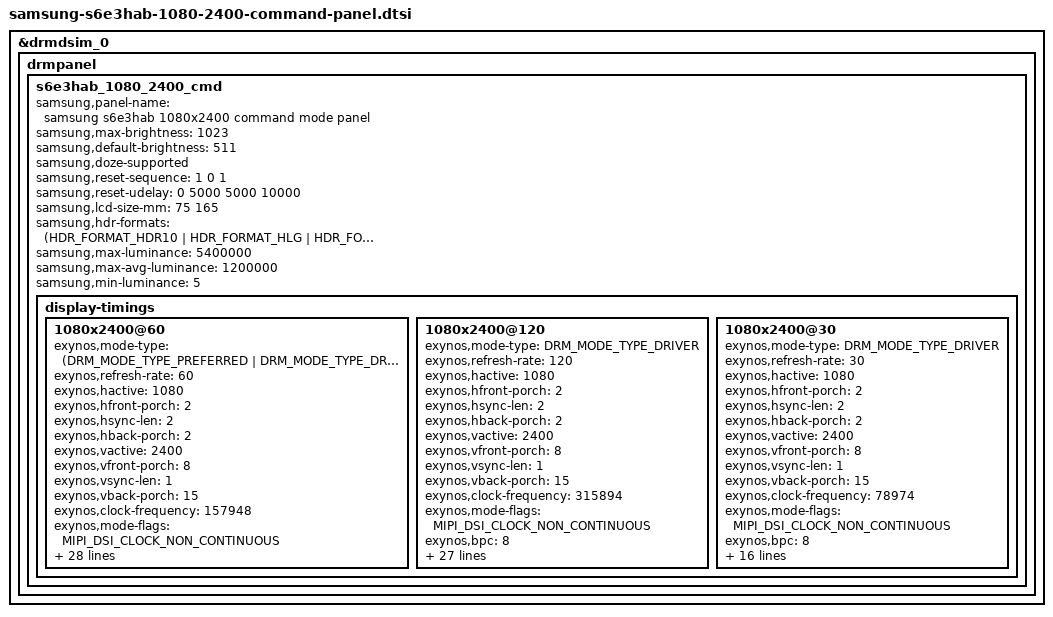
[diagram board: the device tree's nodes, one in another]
#include <dt-bindings/display/exynos-display.h>
#include <dt-bindings/display/exynos-mipi-display.h>

&drmdsim_0 {
	drmpanel {
		s6e3hab_1080_2400_cmd: s6e3hab_1080_2400_cmd {
			samsung,panel-name = "samsung s6e3hab 1080x2400 command mode panel";
			samsung,max-brightness = <1023>;
			samsung,default-brightness = <511>;
			samsung,doze-supported;

			samsung,reset-sequence = <1 0 1>;
			samsung,reset-udelay = <0 5000 5000 10000>;

			samsung,lcd-size-mm = <75 165>; /* width x height */

			samsung,hdr-formats = <(HDR_FORMAT_HDR10 | HDR_FORMAT_HLG | HDR_FORMAT_HDR10P)>;
			samsung,max-luminance = <5400000>;
			samsung,max-avg-luminance = <1200000>;
			samsung,min-luminance = <5>;

			display-timings {
				1080x2400@60 {
					exynos,mode-type = <(DRM_MODE_TYPE_PREFERRED |
							DRM_MODE_TYPE_DRIVER)>;
					exynos,refresh-rate = <60>;
					exynos,hactive = <1080>;
					exynos,hfront-porch = <2>;
					exynos,hsync-len = <2>;
					exynos,hback-porch = <2>;
					exynos,vactive = <2400>;
					exynos,vfront-porch = <8>;
					exynos,vsync-len = <1>;
					exynos,vback-porch = <15>;
					exynos,clock-frequency = <157948>;

					exynos,mode-flags = <MIPI_DSI_CLOCK_NON_CONTINUOUS>;
					exynos,bpc = <8>;
					exynos,lp-mode = <0>;
					exynos,dsc-en = <1>;
					exynos,dsc-count = <1>;
					exynos,dsc-slice-count = <2>;
					exynos,dsc-slice-height = <40>;

					exynos,pre-pps-cmds = <
						0x03 0x9F 0xA5 0xA5 0x00
						>;
					exynos,pps-cmds = <
						0x58
						0x11 0x00 0x00 0x89 0x30 0x80 0x09 0x60
						0x04 0x38 0x00 0x28 0x02 0x1C 0x02 0x1C
						0x02 0x00 0x02 0x0E 0x00 0x20 0x03 0xDD
						0x00 0x07 0x00 0x0C 0x02 0x77 0x02 0x8B
						0x18 0x00 0x10 0xF0 0x03 0x0C 0x20 0x00
						0x06 0x0B 0x0B 0x33 0x0E 0x1C 0x2A 0x38
						0x46 0x54 0x62 0x69 0x70 0x77 0x79 0x7B
						0x7D 0x7E 0x01 0x02 0x01 0x00 0x09 0x40
						0x09 0xBE 0x19 0xFC 0x19 0xFA 0x19 0xF8
						0x1A 0x38 0x1A 0x78 0x1A 0xB6 0x2A 0xF6
						0x2B 0x34 0x2B 0x74 0x3B 0x74 0x6B 0xF4
						0x00
						>;
					exynos,post-pps-cmds = <
						0x03 0x9F 0x5A 0x5A 0x00
						>;
					exynos,on-cmds = <
						0x03 0xF0 0x5A 0x5A 0x00
						0x03 0xFC 0x5A 0x5A 0x00
						/* sleep out: 200ms delay */
						0x01 0x11 0xC8
						0x0A 0xB9 0x00 0xC0 0x8C 0x09 0x00 0x00 0x00 0x11 0x03 0x00
						/*  enable brightness control */
						0x02 0x53 0x20 0x00

						/* WRDISBV(51h) = 1st[7:0], 2nd[15:8] */
						0x03 0x51 0xFF 0x7F 0x00

						/* TE on */
						0x01 0x35 0x00

						/* ESD flag: [2]=VLIN3, [6]=VLIN1 error check */
						0x03 0xED 0x04 0x44 0x00
						/* Typical high duration */
						0x05 0xB9 0x00 0xC0 0x8C 0x09 0x00
						>;
					exynos,tectrl-cmds = <
						0x03 0xF0 0x5A 0x5A 0x00
						0x05 0xB9 0x01 0xB0 0xC4 0x09 0x00
						0x03 0xF0 0xA5 0xA5 0x00
						>;
					exynos,vref-cmds = <
						0x03 0xF0 0x5A 0x5A 0x00
						0x03 0x9F 0xA5 0xA5 0x00
						0x02 0x60 0x00 0x00
						0x03 0x9F 0x5A 0x5A 0x00
						0x02 0xF7 0x0F 0x00
						0x03 0xF0 0xA5 0xA5 0x00
						>;
					exynos,mres-cmds = <
						0x05 0x2A 0x00 0x00 0x04 0x37 0x00
						0x05 0x2B 0x00 0x00 0x09 0x5F 0x00
						0x03 0xF0 0x5A 0x5A 0x00
						0x02 0xBA 0x02 0x00
						0x03 0xF0 0xA5 0xA5 0x00
						>;
					exynos,disp-on-cmds = <
						0x03 0x9F 0xA5 0xA5 0x00
						0x01 0x29 0x00
						0x03 0x9F 0x5A 0x5A 0x00
						>;
					exynos,off-cmds = <
						0x01 0x10 0x00
						0x01 0x28 0x00
						>;

					exynos,rcd-block-rect = <0 100 1080 2200>;
					exynos,rcd-top-pos = <0 0>;
					exynos,rcd-top-img = /bits/ 8 <
						0xFF 0xFF 0xFF 0xFF 0xFF 0xFF 0xFF 0xFF 0xFF 0xFF 0xFF 0xFF 0xFF 0xFF 0xFF 0xFF
						0xFF 0xFF 0xFF 0xFF 0xFF 0x95 0x00 0x03 0xFF 0xFF 0xFF 0xFF 0xFF 0xFF 0xFF 0xFF
						0xFF 0x38 0x00 0x05 0xFF 0xFF 0xFF 0xFF 0xFF 0xFF 0xFF 0xFF 0xFF 0x36 0x00 0x07
						0xFF 0xFF 0xFF 0xFF 0xFF 0xFF 0xFF 0xFF 0xFF 0x34 0x00 0x09 0xFF 0xFF 0xFF 0xFF
						0xFF 0xFF 0xFF 0xFF 0xFF 0x32 0x00 0x0B 0xFF 0xFF 0xFF 0xFF 0xFF 0xFF 0xFF 0xFF
						0xFF 0x30 0x00 0x0D 0xFF 0xFF 0xFF 0xFF 0xFF 0xFF 0xFF 0xFF 0xFF 0x2E 0x00 0x0F
						0xFF 0xFF 0xFF 0xFF 0xFF 0xFF 0xFF 0xFF 0xFF 0x2C 0x00 0x11 0xFF 0xFF 0xFF 0xFF
						0xFF 0xFF 0xFF 0xFF 0xFF 0x2A 0x00 0x13 0xFF 0xFF 0xFF 0xFF 0xFF 0xFF 0xFF 0xFF
						0xFF 0x28 0x00 0x15 0xFF 0xFF 0xFF 0xFF 0xFF 0xFF 0xFF 0xFF 0xFF 0x26 0x00 0x17
						0xFF 0xFF 0xFF 0xFF 0xFF 0xFF 0xFF 0xFF 0xFF 0x24 0x00 0x19 0xFF 0xFF 0xFF 0xFF
						0xFF 0xFF 0xFF 0xFF 0xFF 0x22 0x00 0x1B 0xFF 0xFF 0xFF 0xFF 0xFF 0xFF 0xFF 0xFF
						0xFF 0x20 0x00 0x1D 0xFF 0xFF 0xFF 0xFF 0xFF 0xFF 0xFF 0xFF 0xFF 0x1E 0x00 0x1F
						0xFF 0xFF 0xFF 0xFF 0xFF 0xFF 0xFF 0xFF 0xFF 0x1C 0x00 0x21 0xFF 0xFF 0xFF 0xFF
						0xFF 0xFF 0xFF 0xFF 0xFF 0x1A 0x00 0x23 0xFF 0xFF 0xFF 0xFF 0xFF 0xFF 0xFF 0xFF
						0xFF 0x18 0x00 0x25 0xFF 0xFF 0xFF 0xFF 0xFF 0xFF 0xFF 0xFF 0xFF 0x16 0x00 0x27
						0xFF 0xFF 0xFF 0xFF 0xFF 0xFF 0xFF 0xFF 0xFF 0x14 0x00 0x29 0xFF 0xFF 0xFF 0xFF
						0xFF 0xFF 0xFF 0xFF 0xFF 0x12 0x00 0x2B 0xFF 0xFF 0xFF 0xFF 0xFF 0xFF 0xFF 0xFF
						0xFF 0x10 0x00 0x2D 0xFF 0xFF 0xFF 0xFF 0xFF 0xFF 0xFF 0xFF 0xFF 0x0E 0x00 0x2F
						0xFF 0xFF 0xFF 0xFF 0xFF 0xFF 0xFF 0xFF 0xFF 0x0C 0x00 0x31 0xFF 0xFF 0xFF 0xFF
						0xFF 0xFF 0xFF 0xFF 0xFF 0x0A 0x00 0x33 0xFF 0xFF 0xFF 0xFF 0xFF 0xFF 0xFF 0xFF
						0xFF 0x08 0x00 0x35 0xFF 0xFF 0xFF 0xFF 0xFF 0xFF 0xFF 0xFF 0xFF 0x06 0x00 0x37
						0xFF 0xFF 0xFF 0xFF 0xFF 0xFF 0xFF 0xFF 0xFF 0x04 0x00 0x39 0xFF 0xFF 0xFF 0xFF
						0xFF 0xFF 0xFF 0xFF 0xFF 0x02 0x00 0x3B 0xFF 0xFF 0xFF 0xFF 0xFF 0xFF 0xFF 0xFF
						0x00 0x3D 0xFF 0xFF 0xFF 0xFF 0xFF 0xFF 0xFF 0xFD 0x00 0x3F 0xFF 0xFF 0xFF 0xFF
						0xFF 0xFF 0xFF 0xFB 0x00 0x41 0xFF 0xFF 0xFF 0xFF 0xFF 0xFF 0xFF 0xF9 0x00 0x43
						0xFF 0xFF 0xFF 0xFF 0xFF 0xFF 0xFF 0xF7 0x00 0x45 0xFF 0xFF 0xFF 0xFF 0xFF 0xFF
						0xFF 0xF5 0x00 0x47 0xFF 0xFF 0xFF 0xFF 0xFF 0xFF 0xFF 0xF3 0x00 0x49 0xFF 0xFF
						0xFF 0xFF 0xFF 0xFF 0xFF 0xF1 0x00 0x4B 0xFF 0xFF 0xFF 0xFF 0xFF 0xFF 0xFF 0xEF
						0x00 0x4D 0xFF 0xFF 0xFF 0xFF 0xFF 0xFF 0xFF 0xED 0x00 0x4F 0xFF 0xFF 0xFF 0xFF
						0xFF 0xFF 0xFF 0xEB 0x00 0x51 0xFF 0xFF 0xFF 0xFF 0xFF 0xFF 0xFF 0xE9 0x00 0x53
						0xFF 0xFF 0xFF 0xFF 0xFF 0xFF 0xFF 0xE7 0x00 0x55 0xFF 0xFF 0xFF 0xFF 0xFF 0xFF
						0xFF 0xE6 0x00 0x55 0xFF 0xFF 0xFF 0xFF 0xFF 0xFF 0xFF 0xE6 0x00 0x55 0xFF 0xFF
						0xFF 0xFF 0xFF 0xFF 0xFF 0xE7 0x00 0x53 0xFF 0xFF 0xFF 0xFF 0xFF 0xFF 0xFF 0xE9
						0x00 0x51 0xFF 0xFF 0xFF 0xFF 0xFF 0xFF 0xFF 0xEB 0x00 0x4F 0xFF 0xFF 0xFF 0xFF
						0xFF 0xFF 0xFF 0xED 0x00 0x4D 0xFF 0xFF 0xFF 0xFF 0xFF 0xFF 0xFF 0xEF 0x00 0x4B
						0xFF 0xFF 0xFF 0xFF 0xFF 0xFF 0xFF 0xF1 0x00 0x49 0xFF 0xFF 0xFF 0xFF 0xFF 0xFF
						0xFF 0xF3 0x00 0x47 0xFF 0xFF 0xFF 0xFF 0xFF 0xFF 0xFF 0xF5 0x00 0x45 0xFF 0xFF
						0xFF 0xFF 0xFF 0xFF 0xFF 0xF7 0x00 0x43 0xFF 0xFF 0xFF 0xFF 0xFF 0xFF 0xFF 0xF9
						0x00 0x41 0xFF 0xFF 0xFF 0xFF 0xFF 0xFF 0xFF 0xFB 0x00 0x3F 0xFF 0xFF 0xFF 0xFF
						0xFF 0xFF 0xFF 0xFD 0x00 0x3D 0xFF 0xFF 0xFF 0xFF 0xFF 0xFF 0xFF 0xFF 0x00 0x3B
						0xFF 0xFF 0xFF 0xFF 0xFF 0xFF 0xFF 0xFF 0xFF 0x02 0x00 0x39 0xFF 0xFF 0xFF 0xFF
						0xFF 0xFF 0xFF 0xFF 0xFF 0x04 0x00 0x37 0xFF 0xFF 0xFF 0xFF 0xFF 0xFF 0xFF 0xFF
						0xFF 0x06 0x00 0x35 0xFF 0xFF 0xFF 0xFF 0xFF 0xFF 0xFF 0xFF 0xFF 0x08 0x00 0x33
						0xFF 0xFF 0xFF 0xFF 0xFF 0xFF 0xFF 0xFF 0xFF 0x0A 0x00 0x31 0xFF 0xFF 0xFF 0xFF
						0xFF 0xFF 0xFF 0xFF 0xFF 0x0C 0x00 0x2F 0xFF 0xFF 0xFF 0xFF 0xFF 0xFF 0xFF 0xFF
						0xFF 0x0E 0x00 0x2D 0xFF 0xFF 0xFF 0xFF 0xFF 0xFF 0xFF 0xFF 0xFF 0x10 0x00 0x2B
						0xFF 0xFF 0xFF 0xFF 0xFF 0xFF 0xFF 0xFF 0xFF 0x12 0x00 0x29 0xFF 0xFF 0xFF 0xFF
						0xFF 0xFF 0xFF 0xFF 0xFF 0x14 0x00 0x27 0xFF 0xFF 0xFF 0xFF 0xFF 0xFF 0xFF 0xFF
						0xFF 0x16 0x00 0x25 0xFF 0xFF 0xFF 0xFF 0xFF 0xFF 0xFF 0xFF 0xFF 0x18 0x00 0x23
						0xFF 0xFF 0xFF 0xFF 0xFF 0xFF 0xFF 0xFF 0xFF 0x1A 0x00 0x21 0xFF 0xFF 0xFF 0xFF
						0xFF 0xFF 0xFF 0xFF 0xFF 0x1C 0x00 0x1F 0xFF 0xFF 0xFF 0xFF 0xFF 0xFF 0xFF 0xFF
						0xFF 0x1E 0x00 0x1D 0xFF 0xFF 0xFF 0xFF 0xFF 0xFF 0xFF 0xFF 0xFF 0x20 0x00 0x1B
						0xFF 0xFF 0xFF 0xFF 0xFF 0xFF 0xFF 0xFF 0xFF 0x22 0x00 0x19 0xFF 0xFF 0xFF 0xFF
						0xFF 0xFF 0xFF 0xFF 0xFF 0x24 0x00 0x17 0xFF 0xFF 0xFF 0xFF 0xFF 0xFF 0xFF 0xFF
						0xFF 0x26 0x00 0x15 0xFF 0xFF 0xFF 0xFF 0xFF 0xFF 0xFF 0xFF 0xFF 0x28 0x00 0x13
						0xFF 0xFF 0xFF 0xFF 0xFF 0xFF 0xFF 0xFF 0xFF 0x2A 0x00 0x11 0xFF 0xFF 0xFF 0xFF
						0xFF 0xFF 0xFF 0xFF 0xFF 0x2C 0x00 0x0F 0xFF 0xFF 0xFF 0xFF 0xFF 0xFF 0xFF 0xFF
						0xFF 0x2E 0x00 0x0D 0xFF 0xFF 0xFF 0xFF 0xFF 0xFF 0xFF 0xFF 0xFF 0x30 0x00 0x0B
						0xFF 0xFF 0xFF 0xFF 0xFF 0xFF 0xFF 0xFF 0xFF 0x32 0x00 0x09 0xFF 0xFF 0xFF 0xFF
						0xFF 0xFF 0xFF 0xFF 0xFF 0x34 0x00 0x07 0xFF 0xFF 0xFF 0xFF 0xFF 0xFF 0xFF 0xFF
						0xFF 0x36 0x00 0x05 0xFF 0xFF 0xFF 0xFF 0xFF 0xFF 0xFF 0xFF 0xFF 0x38 0x00 0x03
						0xFF 0xFF 0xFF 0xFF 0xFF 0xFF 0xFF 0xFF 0xFF 0xFF 0xFF 0xFF 0xFF 0xFF 0xFF 0xFF
						0xFF 0xFF 0xFF 0xFF 0xFF 0xFF 0xFF 0xFF 0xFF 0xFF 0xFF 0xFF 0xFF 0xFF 0xFF 0xFF
						0xFF 0xFF 0xFF 0xFF 0xFF 0xFF 0xFF 0xFF 0xFF 0xFF 0xFF 0xFF 0xFF 0xFF 0xFF 0xFF
						0xFF 0xFF 0xFF 0xFF 0xFF 0xFF 0xFF 0xFF 0xFF 0xFF 0xFF 0xFF 0xFF 0xFF 0xFF 0xFF
						0xFF 0xFF 0xFF 0xFF 0xFF 0xFF 0xFF 0xFF 0xFF 0xFF 0xFF 0xFF 0xFF 0xFF 0xFF 0xFF
						0xFF 0xFF 0xFF 0xFF 0xFF 0xFF 0xFF 0xFF 0xFF 0xFF 0xFF 0xFF 0xFF 0xFF 0xFF 0xFF
						0xFF 0xFF 0xFF 0xFF 0xFF 0xFF 0xFF 0xFF 0xFF 0xFF 0xFF 0xFF 0xFF 0xFF 0xFF 0xFF
						0xFF 0xFF 0xFF 0x2B
						>;

					exynos,rcd-bot-pos = <0 2300>;
					exynos,rcd-bot-img = /bits/ 8 <
						0xFF 0xFF 0xFF 0xFF 0xFF 0xFF 0xFF 0xFF 0xFF 0xFF 0xFF 0xFF 0xFF 0xFF 0xFF 0xFF
						0xFF 0xFF 0xFF 0xFF 0xFF 0xFF 0xFF 0xFF 0xFF 0xFF 0xFF 0xFF 0xFF 0xFF 0xFF 0xFF
						0xFF 0xFF 0xFF 0xFF 0xFF 0xFF 0xFF 0xFF 0xFF 0xFF 0xFF 0xFF 0xFF 0xFF 0xFF 0xFF
						0xFF 0xFF 0xFF 0xFF 0xFF 0xFF 0xFF 0xFF 0xFF 0xFF 0xFF 0xFF 0xFF 0xFF 0xFF 0xFF
						0xFF 0xFF 0xFF 0xFF 0xFF 0xFF 0xFF 0xFF 0xFF 0xFF 0xFF 0xFF 0xFF 0xFF 0xFF 0xFF
						0xFF 0xFF 0xFF 0xFF 0xFF 0xFF 0xFF 0xFF 0xFF 0xFF 0xFF 0xFF 0xFF 0xFF 0xFF 0xFF
						0xFF 0xFF 0xFF 0xFF 0xFF 0xFF 0xFF 0xFF 0xFF 0xFF 0xFF 0xFF 0xFF 0xFF 0xFF 0xFF
						0xFF 0xFF 0xFF 0xFF 0xFF 0xFF 0xFF 0xFF 0xFF 0xFF 0xFF 0xFF 0xFF 0xFF 0xFF 0xFF
						0xFF 0xFF 0xFF 0xFF 0xFF 0xFF 0xFF 0xFF 0xFF 0xFF 0xFF 0xFF 0xFF 0xFF 0xFF 0xFF
						0xFF 0xFF 0xFF 0xFF 0xFF 0xFF 0xFF 0xFF 0xFF 0xFF 0xFF 0xFF 0xFF 0xFF 0xFF 0xFF
						0xFF 0xFF 0xFF 0xFF 0xFF 0xFF 0xFF 0xFF 0xFF 0xFF 0xFF 0xFF 0xFF 0xFF 0xFF 0xFF
						0xFF 0xFF 0xFF 0xFF 0xFF 0xFF 0xFF 0xFF 0xFF 0xFF 0xFF 0xFF 0xFF 0xFF 0xFF 0xFF
						0xFF 0xFF 0xFF 0xFF 0xFF 0xFF 0xFF 0xFF 0xFF 0xFF 0xFF 0xFF 0xFF 0xFF 0xFF 0xFF
						0xFF 0xFF 0xFF 0xFF 0xFF 0xFF 0xFF 0xFF 0xFF 0xFF 0xFF 0xFF 0xFF 0xFF 0xFF 0xFF
						0xFF 0xFF 0xFF 0xFF 0xFF 0xFF 0xFF 0xFF 0xFF 0xFF 0xFF 0xFF 0xFF 0xFF 0xFF 0xFF
						0xFF 0xFF 0xFF 0xFF 0xFF 0xFF 0xFF 0xFF 0xFF 0xFF 0xFF 0xFF 0xFF 0xFF 0xFF 0xFF
						0xFF 0xFF 0xFF 0xFF 0xFF 0xFF 0xFF 0xFF 0xFF 0xFF 0xFF 0xFF 0xFF 0xFF 0xFF 0xFF
						0xFF 0xFF 0xFF 0xFF 0xFF 0xFF 0xFF 0xFF 0xFF 0xFF 0xFF 0xFF 0xFF 0xFF 0xFF 0xFF
						0xFF 0xFF 0xFF 0xFF 0xFF 0xFF 0xFF 0xFF 0xFF 0xFF 0xFF 0xFF 0xFF 0xFF 0xFF 0xFF
						0xFF 0xFF 0xFF 0xFF 0xFF 0xFF 0xFF 0xFF 0xFF 0xFF 0xFF 0xFF 0xFF 0xFF 0xFF 0xFF
						0xFF 0xFF 0xFF 0xFF 0xFF 0xFF 0xFF 0xFF 0xFF 0xFF 0xFF 0xFF 0xFF 0xFF 0xFF 0xFF
						0xFF 0xFF 0xFF 0xFF 0xFF 0xFF 0xFF 0xFF 0xFF 0xFF 0xFF 0xFF 0xFF 0xFF 0xFF 0xFF
						0xFF 0xFF 0xFF 0xFF 0xFF 0xFF 0xFF 0xFF 0xFF 0xFF 0xFF 0xFF 0xFF 0xFF 0xFF 0xFF
						0xFF 0xFF 0xFF 0xFF 0xFF 0xFF 0xFF 0xFF 0xFF 0xFF 0xFF 0xFF 0xFF 0xFF 0xFF 0xFF
						0xFF 0xFF 0xFF 0xFF 0xFF 0xFF 0xFF 0xFF 0xFF 0xFF 0xFF 0xFF 0xFF 0xFF 0xFF 0xFF
						0xFF 0xFF 0xFF 0xFF 0xFF 0xFF 0xFF 0xFF 0xFF 0xFF 0xFF 0xFF 0xFF 0xFF 0xFF 0xFF
						0xFF 0xFF 0xFF 0xFF 0xFF 0xFF 0xFF 0xFF 0xFF 0xFF 0xFF 0xFF 0xFF 0xFF 0xFF 0xFF
						0xFF 0xFF 0xFF 0xFF 0xFF 0xFF 0xFF 0xFF 0xFF 0xFF 0xFF 0xFF 0xFF 0xFF 0xFF 0xFF
						0xFF 0xFF 0xFF 0xFF 0xFF 0xFF 0xFF 0xFF 0xFF 0xFF 0xFF 0xFF 0xFF 0xFF 0xFF 0xFF
						0xFF 0xFF 0xFF 0xFF 0xFF 0xFF 0xFF 0xFF 0xFF 0xFF 0xFF 0xFF 0xFF 0xFF 0xFF 0xFF
						0xFF 0xFF 0xFF 0xFF 0xFF 0xFF 0xFF 0xFF 0xFF 0xFF 0xFF 0xFF 0xFF 0xFF 0xFF 0xFF
						0xFF 0xFF 0xFF 0xFF 0xFF 0xFF 0xFF 0xFF 0xFF 0xFF 0xFF 0xFF 0xFF 0xFF 0xFF 0xFF
						0xFF 0xFF 0xFF 0xFF 0xFF 0xFF 0xFF 0xFF 0xFF 0xFF 0xFF 0xFF 0xFF 0xFF 0xFF 0xFF
						0xFF 0xFF 0xFF 0xFF 0xFF 0xFF 0xFF 0xFF 0xFF 0xFF 0xFF 0xFF 0xFF 0xFF 0xFF 0xFF
						0xFF 0xFF 0xFF 0xFF 0xFF 0xFF 0xFF 0xFF 0xFF 0xFF 0xFF 0xFF 0xFF 0xFF 0xFF 0xFF
						0xFF 0xFF 0xFF 0xFF 0xFF 0xFF 0xFF 0xFF 0xFF 0xFF 0xFF 0xFF 0xFF 0xFF 0xFF 0xFF
						0xFF 0xFF 0xFF 0xFF 0xFF 0xFF 0xFF 0xFF 0xFF 0xFF 0xFF 0xFF 0xFF 0xFF 0xFF 0xFF
						0xFF 0xFF 0xFF 0xFF 0xFF 0xFF 0xFF 0xFF 0xFF 0xFF 0xFF 0xFF 0xFF 0xFF 0xFF 0xFF
						0xFF 0xFF 0xFF 0xFF 0xFF 0xFF 0xFF 0xFF 0xFF 0xFF 0xFF 0xFF 0xFF 0xFF 0xFF 0xFF
						0xFF 0xFF 0xFF 0xFF 0xFF 0xFF 0xFF 0xFF 0xFF 0xFF 0xFF 0xFF 0xFF 0xFF 0xFF 0xFF
						0xFF 0xFF 0xFF 0xFF 0xFF 0xFF 0xFF 0xFF 0xFF 0xFF 0xFF 0xFF 0xFF 0xFF 0xFF 0xFF
						0xFF 0xFF 0xFF 0xFF 0xFF 0xFF 0xFF 0xFF 0xFF 0xFF 0xFF 0xFF 0xFF 0xFF 0xFF 0xFF
						0xFF 0xFF 0xFF 0xFF 0xFF 0xFF 0xFF 0xFF 0xFF 0xFF 0xFF 0xFF 0xFF 0xFF 0xFF 0xFF
						0xFF 0xFF 0xFF 0xFF 0xFF 0xFF 0xFF 0xFF 0xFF 0xFF 0xFF 0xFF 0xFF 0xFF 0xFF 0xFF
						0xFF 0xFF 0xFF 0xFF 0xFF 0xFF 0xFF 0xFF 0xFF 0xFF 0xFF 0xFF 0xFF 0xFF 0xFF 0xFF
						0xFF 0xFF 0xFF 0xFF 0xFF 0xFF 0xFF 0xFF 0xFF 0xFF 0xFF 0xFF 0xFF 0xFF 0xFF 0xFF
						0xFF 0xFF 0xFF 0xFF 0xFF 0xFF 0xFF 0xFF 0xFF 0xFF 0xFF 0xFF 0xFF 0xFF 0xFF 0xFF
						0xFF 0xFF 0xFF 0xFF 0xFF 0xFF 0xFF 0xFF 0xFF 0xFF 0xFF 0xFF 0xFF 0xFF 0xFF 0xFF
						0xFF 0xFF 0xFF 0xFF 0xFF 0xFF 0xFF 0xFF 0xFF 0xFF 0xFF 0xFF 0xFF 0xFF 0xFF 0xFF
						0xFF 0xFF 0xFF 0xFF 0xFF 0xFF 0xFF 0xFF 0xFF 0xFF 0xFF 0xFF 0xFF 0xFF 0xFF 0xFF
						0xFF 0xFF 0xFF 0xFF 0xFF 0xFF 0xFF 0xFF 0xFF 0xFF 0xFF 0xFF 0xFF 0xFF 0xFF 0xFF
						0xFF 0xFF 0xFF 0xFF 0xFF 0xFF 0xFF 0xFF 0xFF 0xFF 0xFF 0xFF 0xFF 0xFF 0xFF 0xFF
						0xFF 0xFF 0xFF 0xFF 0xFF 0xFF 0xFF 0xFF 0xFF 0xFF 0xFF 0xFF 0xFF 0xFF 0xFF 0x87
						>;
				};
				1080x2400@120 {
					exynos,mode-type = <DRM_MODE_TYPE_DRIVER>;
					exynos,refresh-rate = <120>;
					exynos,hactive = <1080>;
					exynos,hfront-porch = <2>;
					exynos,hsync-len = <2>;
					exynos,hback-porch = <2>;
					exynos,vactive = <2400>;
					exynos,vfront-porch = <8>;
					exynos,vsync-len = <1>;
					exynos,vback-porch = <15>;
					exynos,clock-frequency = <315894>;

					exynos,mode-flags = <MIPI_DSI_CLOCK_NON_CONTINUOUS>;
					exynos,bpc = <8>;
					exynos,lp-mode = <0>;
					exynos,dsc-en = <1>;
					exynos,dsc-count = <1>;
					exynos,dsc-slice-count = <2>;
					exynos,dsc-slice-height = <40>;

					exynos,pre-pps-cmds = <
						0x03 0x9F 0xA5 0xA5 0x00
						>;
					exynos,pps-cmds = <
						0x58
						0x11 0x00 0x00 0x89 0x30 0x80 0x09 0x60
						0x04 0x38 0x00 0x28 0x02 0x1C 0x02 0x1C
						0x02 0x00 0x02 0x0E 0x00 0x20 0x03 0xDD
						0x00 0x07 0x00 0x0C 0x02 0x77 0x02 0x8B
						0x18 0x00 0x10 0xF0 0x03 0x0C 0x20 0x00
						0x06 0x0B 0x0B 0x33 0x0E 0x1C 0x2A 0x38
						0x46 0x54 0x62 0x69 0x70 0x77 0x79 0x7B
						0x7D 0x7E 0x01 0x02 0x01 0x00 0x09 0x40
						0x09 0xBE 0x19 0xFC 0x19 0xFA 0x19 0xF8
						0x1A 0x38 0x1A 0x78 0x1A 0xB6 0x2A 0xF6
						0x2B 0x34 0x2B 0x74 0x3B 0x74 0x6B 0xF4
						0x00
						>;
					exynos,post-pps-cmds = <
						0x03 0x9F 0x5A 0x5A 0x00
						>;
					exynos,on-cmds = <
						0x03 0xF0 0x5A 0x5A 0x00
						0x03 0xFC 0x5A 0x5A 0x00
						/* sleep out: 200ms delay */
						0x01 0x11 0xC8
						0x0A 0xB9 0x00 0xC0 0x8C 0x09 0x00 0x00 0x00 0x11 0x03 0x00
						/*  enable brightness control */
						0x02 0x53 0x20 0x00

						/* WRDISBV(51h) = 1st[7:0], 2nd[15:8] */
						0x03 0x51 0xFF 0x7F 0x00

						/* TE on */
						0x01 0x35 0x00

						/* ESD flag: [2]=VLIN3, [6]=VLIN1 error check */
						0x03 0xED 0x04 0x44 0x00
						/* Typical high duration */
						0x05 0xB9 0x00 0xC0 0x8C 0x09 0x00
						>;
					exynos,tectrl-cmds = <
						0x03 0xF0 0x5A 0x5A 0x00
						0x05 0xB9 0x01 0xA0 0xFC 0x09 0x00
						0x03 0xF0 0xA5 0xA5 0x00
						>;
					exynos,vref-cmds = <
						0x03 0xF0 0x5A 0x5A 0x00
						0x03 0x9F 0xA5 0xA5 0x00
						0x02 0x60 0x20 0x00
						0x03 0x9F 0x5A 0x5A 0x00
						0x02 0xF7 0x0F 0x00
						0x03 0xF0 0xA5 0xA5 0x00
						>;
					exynos,mres-cmds = <
						0x05 0x2A 0x00 0x00 0x04 0x37 0x00
						0x05 0x2B 0x00 0x00 0x09 0x5F 0x00
						0x03 0xF0 0x5A 0x5A 0x00
						0x02 0xBA 0x02 0x00
						0x03 0xF0 0xA5 0xA5 0x00
						>;
					exynos,disp-on-cmds = <
						0x03 0x9F 0xA5 0xA5 0x00
						0x01 0x29 0x00
						0x03 0x9F 0x5A 0x5A 0x00
						>;
					exynos,off-cmds = <
						0x01 0x10 0x00
						0x01 0x28 0x00
						>;

					exynos,rcd-block-rect = <0 100 1080 2200>;
					exynos,rcd-top-pos = <0 0>;
					exynos,rcd-top-img = /bits/ 8 <
						0xFF 0xFF 0xFF 0xFF 0xFF 0xFF 0xFF 0xFF 0xFF 0xFF 0xFF 0xFF 0xFF 0xFF 0xFF 0xFF
						0xFF 0xFF 0xFF 0xFF 0xFF 0x95 0x00 0x03 0xFF 0xFF 0xFF 0xFF 0xFF 0xFF 0xFF 0xFF
						0xFF 0x38 0x00 0x05 0xFF 0xFF 0xFF 0xFF 0xFF 0xFF 0xFF 0xFF 0xFF 0x36 0x00 0x07
						0xFF 0xFF 0xFF 0xFF 0xFF 0xFF 0xFF 0xFF 0xFF 0x34 0x00 0x09 0xFF 0xFF 0xFF 0xFF
						0xFF 0xFF 0xFF 0xFF 0xFF 0x32 0x00 0x0B 0xFF 0xFF 0xFF 0xFF 0xFF 0xFF 0xFF 0xFF
						0xFF 0x30 0x00 0x0D 0xFF 0xFF 0xFF 0xFF 0xFF 0xFF 0xFF 0xFF 0xFF 0x2E 0x00 0x0F
						0xFF 0xFF 0xFF 0xFF 0xFF 0xFF 0xFF 0xFF 0xFF 0x2C 0x00 0x11 0xFF 0xFF 0xFF 0xFF
						0xFF 0xFF 0xFF 0xFF 0xFF 0x2A 0x00 0x13 0xFF 0xFF 0xFF 0xFF 0xFF 0xFF 0xFF 0xFF
						0xFF 0x28 0x00 0x15 0xFF 0xFF 0xFF 0xFF 0xFF 0xFF 0xFF 0xFF 0xFF 0x26 0x00 0x17
						0xFF 0xFF 0xFF 0xFF 0xFF 0xFF 0xFF 0xFF 0xFF 0x24 0x00 0x19 0xFF 0xFF 0xFF 0xFF
						0xFF 0xFF 0xFF 0xFF 0xFF 0x22 0x00 0x1B 0xFF 0xFF 0xFF 0xFF 0xFF 0xFF 0xFF 0xFF
						0xFF 0x20 0x00 0x1D 0xFF 0xFF 0xFF 0xFF 0xFF 0xFF 0xFF 0xFF 0xFF 0x1E 0x00 0x1F
						0xFF 0xFF 0xFF 0xFF 0xFF 0xFF 0xFF 0xFF 0xFF 0x1C 0x00 0x21 0xFF 0xFF 0xFF 0xFF
						0xFF 0xFF 0xFF 0xFF 0xFF 0x1A 0x00 0x23 0xFF 0xFF 0xFF 0xFF 0xFF 0xFF 0xFF 0xFF
						0xFF 0x18 0x00 0x25 0xFF 0xFF 0xFF 0xFF 0xFF 0xFF 0xFF 0xFF 0xFF 0x16 0x00 0x27
						0xFF 0xFF 0xFF 0xFF 0xFF 0xFF 0xFF 0xFF 0xFF 0x14 0x00 0x29 0xFF 0xFF 0xFF 0xFF
						0xFF 0xFF 0xFF 0xFF 0xFF 0x12 0x00 0x2B 0xFF 0xFF 0xFF 0xFF 0xFF 0xFF 0xFF 0xFF
						0xFF 0x10 0x00 0x2D 0xFF 0xFF 0xFF 0xFF 0xFF 0xFF 0xFF 0xFF 0xFF 0x0E 0x00 0x2F
						0xFF 0xFF 0xFF 0xFF 0xFF 0xFF 0xFF 0xFF 0xFF 0x0C 0x00 0x31 0xFF 0xFF 0xFF 0xFF
						0xFF 0xFF 0xFF 0xFF 0xFF 0x0A 0x00 0x33 0xFF 0xFF 0xFF 0xFF 0xFF 0xFF 0xFF 0xFF
						0xFF 0x08 0x00 0x35 0xFF 0xFF 0xFF 0xFF 0xFF 0xFF 0xFF 0xFF 0xFF 0x06 0x00 0x37
						0xFF 0xFF 0xFF 0xFF 0xFF 0xFF 0xFF 0xFF 0xFF 0x04 0x00 0x39 0xFF 0xFF 0xFF 0xFF
						0xFF 0xFF 0xFF 0xFF 0xFF 0x02 0x00 0x3B 0xFF 0xFF 0xFF 0xFF 0xFF 0xFF 0xFF 0xFF
						0x00 0x3D 0xFF 0xFF 0xFF 0xFF 0xFF 0xFF 0xFF 0xFD 0x00 0x3F 0xFF 0xFF 0xFF 0xFF
						0xFF 0xFF 0xFF 0xFB 0x00 0x41 0xFF 0xFF 0xFF 0xFF 0xFF 0xFF 0xFF 0xF9 0x00 0x43
						0xFF 0xFF 0xFF 0xFF 0xFF 0xFF 0xFF 0xF7 0x00 0x45 0xFF 0xFF 0xFF 0xFF 0xFF 0xFF
						0xFF 0xF5 0x00 0x47 0xFF 0xFF 0xFF 0xFF 0xFF 0xFF 0xFF 0xF3 0x00 0x49 0xFF 0xFF
						0xFF 0xFF 0xFF 0xFF 0xFF 0xF1 0x00 0x4B 0xFF 0xFF 0xFF 0xFF 0xFF 0xFF 0xFF 0xEF
						0x00 0x4D 0xFF 0xFF 0xFF 0xFF 0xFF 0xFF 0xFF 0xED 0x00 0x4F 0xFF 0xFF 0xFF 0xFF
						0xFF 0xFF 0xFF 0xEB 0x00 0x51 0xFF 0xFF 0xFF 0xFF 0xFF 0xFF 0xFF 0xE9 0x00 0x53
						0xFF 0xFF 0xFF 0xFF 0xFF 0xFF 0xFF 0xE7 0x00 0x55 0xFF 0xFF 0xFF 0xFF 0xFF 0xFF
						0xFF 0xE6 0x00 0x55 0xFF 0xFF 0xFF 0xFF 0xFF 0xFF 0xFF 0xE6 0x00 0x55 0xFF 0xFF
						0xFF 0xFF 0xFF 0xFF 0xFF 0xE7 0x00 0x53 0xFF 0xFF 0xFF 0xFF 0xFF 0xFF 0xFF 0xE9
						0x00 0x51 0xFF 0xFF 0xFF 0xFF 0xFF 0xFF 0xFF 0xEB 0x00 0x4F 0xFF 0xFF 0xFF 0xFF
						0xFF 0xFF 0xFF 0xED 0x00 0x4D 0xFF 0xFF 0xFF 0xFF 0xFF 0xFF 0xFF 0xEF 0x00 0x4B
						0xFF 0xFF 0xFF 0xFF 0xFF 0xFF 0xFF 0xF1 0x00 0x49 0xFF 0xFF 0xFF 0xFF 0xFF 0xFF
						0xFF 0xF3 0x00 0x47 0xFF 0xFF 0xFF 0xFF 0xFF 0xFF 0xFF 0xF5 0x00 0x45 0xFF 0xFF
						0xFF 0xFF 0xFF 0xFF 0xFF 0xF7 0x00 0x43 0xFF 0xFF 0xFF 0xFF 0xFF 0xFF 0xFF 0xF9
						0x00 0x41 0xFF 0xFF 0xFF 0xFF 0xFF 0xFF 0xFF 0xFB 0x00 0x3F 0xFF 0xFF 0xFF 0xFF
						0xFF 0xFF 0xFF 0xFD 0x00 0x3D 0xFF 0xFF 0xFF 0xFF 0xFF 0xFF 0xFF 0xFF 0x00 0x3B
						0xFF 0xFF 0xFF 0xFF 0xFF 0xFF 0xFF 0xFF 0xFF 0x02 0x00 0x39 0xFF 0xFF 0xFF 0xFF
						0xFF 0xFF 0xFF 0xFF 0xFF 0x04 0x00 0x37 0xFF 0xFF 0xFF 0xFF 0xFF 0xFF 0xFF 0xFF
						0xFF 0x06 0x00 0x35 0xFF 0xFF 0xFF 0xFF 0xFF 0xFF 0xFF 0xFF 0xFF 0x08 0x00 0x33
						0xFF 0xFF 0xFF 0xFF 0xFF 0xFF 0xFF 0xFF 0xFF 0x0A 0x00 0x31 0xFF 0xFF 0xFF 0xFF
						0xFF 0xFF 0xFF 0xFF 0xFF 0x0C 0x00 0x2F 0xFF 0xFF 0xFF 0xFF 0xFF 0xFF 0xFF 0xFF
						0xFF 0x0E 0x00 0x2D 0xFF 0xFF 0xFF 0xFF 0xFF 0xFF 0xFF 0xFF 0xFF 0x10 0x00 0x2B
						0xFF 0xFF 0xFF 0xFF 0xFF 0xFF 0xFF 0xFF 0xFF 0x12 0x00 0x29 0xFF 0xFF 0xFF 0xFF
						0xFF 0xFF 0xFF 0xFF 0xFF 0x14 0x00 0x27 0xFF 0xFF 0xFF 0xFF 0xFF 0xFF 0xFF 0xFF
						0xFF 0x16 0x00 0x25 0xFF 0xFF 0xFF 0xFF 0xFF 0xFF 0xFF 0xFF 0xFF 0x18 0x00 0x23
						0xFF 0xFF 0xFF 0xFF 0xFF 0xFF 0xFF 0xFF 0xFF 0x1A 0x00 0x21 0xFF 0xFF 0xFF 0xFF
						0xFF 0xFF 0xFF 0xFF 0xFF 0x1C 0x00 0x1F 0xFF 0xFF 0xFF 0xFF 0xFF 0xFF 0xFF 0xFF
						0xFF 0x1E 0x00 0x1D 0xFF 0xFF 0xFF 0xFF 0xFF 0xFF 0xFF 0xFF 0xFF 0x20 0x00 0x1B
						0xFF 0xFF 0xFF 0xFF 0xFF 0xFF 0xFF 0xFF 0xFF 0x22 0x00 0x19 0xFF 0xFF 0xFF 0xFF
						0xFF 0xFF 0xFF 0xFF 0xFF 0x24 0x00 0x17 0xFF 0xFF 0xFF 0xFF 0xFF 0xFF 0xFF 0xFF
						0xFF 0x26 0x00 0x15 0xFF 0xFF 0xFF 0xFF 0xFF 0xFF 0xFF 0xFF 0xFF 0x28 0x00 0x13
						0xFF 0xFF 0xFF 0xFF 0xFF 0xFF 0xFF 0xFF 0xFF 0x2A 0x00 0x11 0xFF 0xFF 0xFF 0xFF
						0xFF 0xFF 0xFF 0xFF 0xFF 0x2C 0x00 0x0F 0xFF 0xFF 0xFF 0xFF 0xFF 0xFF 0xFF 0xFF
						0xFF 0x2E 0x00 0x0D 0xFF 0xFF 0xFF 0xFF 0xFF 0xFF 0xFF 0xFF 0xFF 0x30 0x00 0x0B
						0xFF 0xFF 0xFF 0xFF 0xFF 0xFF 0xFF 0xFF 0xFF 0x32 0x00 0x09 0xFF 0xFF 0xFF 0xFF
						0xFF 0xFF 0xFF 0xFF 0xFF 0x34 0x00 0x07 0xFF 0xFF 0xFF 0xFF 0xFF 0xFF 0xFF 0xFF
						0xFF 0x36 0x00 0x05 0xFF 0xFF 0xFF 0xFF 0xFF 0xFF 0xFF 0xFF 0xFF 0x38 0x00 0x03
						0xFF 0xFF 0xFF 0xFF 0xFF 0xFF 0xFF 0xFF 0xFF 0xFF 0xFF 0xFF 0xFF 0xFF 0xFF 0xFF
						0xFF 0xFF 0xFF 0xFF 0xFF 0xFF 0xFF 0xFF 0xFF 0xFF 0xFF 0xFF 0xFF 0xFF 0xFF 0xFF
						0xFF 0xFF 0xFF 0xFF 0xFF 0xFF 0xFF 0xFF 0xFF 0xFF 0xFF 0xFF 0xFF 0xFF 0xFF 0xFF
						0xFF 0xFF 0xFF 0xFF 0xFF 0xFF 0xFF 0xFF 0xFF 0xFF 0xFF 0xFF 0xFF 0xFF 0xFF 0xFF
						0xFF 0xFF 0xFF 0xFF 0xFF 0xFF 0xFF 0xFF 0xFF 0xFF 0xFF 0xFF 0xFF 0xFF 0xFF 0xFF
						0xFF 0xFF 0xFF 0xFF 0xFF 0xFF 0xFF 0xFF 0xFF 0xFF 0xFF 0xFF 0xFF 0xFF 0xFF 0xFF
						0xFF 0xFF 0xFF 0xFF 0xFF 0xFF 0xFF 0xFF 0xFF 0xFF 0xFF 0xFF 0xFF 0xFF 0xFF 0xFF
						0xFF 0xFF 0xFF 0x2B
						>;

					exynos,rcd-bot-pos = <0 2300>;
					exynos,rcd-bot-img = /bits/ 8 <
						0xFF 0xFF 0xFF 0xFF 0xFF 0xFF 0xFF 0xFF 0xFF 0xFF 0xFF 0xFF 0xFF 0xFF 0xFF 0xFF
						0xFF 0xFF 0xFF 0xFF 0xFF 0xFF 0xFF 0xFF 0xFF 0xFF 0xFF 0xFF 0xFF 0xFF 0xFF 0xFF
						0xFF 0xFF 0xFF 0xFF 0xFF 0xFF 0xFF 0xFF 0xFF 0xFF 0xFF 0xFF 0xFF 0xFF 0xFF 0xFF
						0xFF 0xFF 0xFF 0xFF 0xFF 0xFF 0xFF 0xFF 0xFF 0xFF 0xFF 0xFF 0xFF 0xFF 0xFF 0xFF
						0xFF 0xFF 0xFF 0xFF 0xFF 0xFF 0xFF 0xFF 0xFF 0xFF 0xFF 0xFF 0xFF 0xFF 0xFF 0xFF
						0xFF 0xFF 0xFF 0xFF 0xFF 0xFF 0xFF 0xFF 0xFF 0xFF 0xFF 0xFF 0xFF 0xFF 0xFF 0xFF
						0xFF 0xFF 0xFF 0xFF 0xFF 0xFF 0xFF 0xFF 0xFF 0xFF 0xFF 0xFF 0xFF 0xFF 0xFF 0xFF
						0xFF 0xFF 0xFF 0xFF 0xFF 0xFF 0xFF 0xFF 0xFF 0xFF 0xFF 0xFF 0xFF 0xFF 0xFF 0xFF
						0xFF 0xFF 0xFF 0xFF 0xFF 0xFF 0xFF 0xFF 0xFF 0xFF 0xFF 0xFF 0xFF 0xFF 0xFF 0xFF
						0xFF 0xFF 0xFF 0xFF 0xFF 0xFF 0xFF 0xFF 0xFF 0xFF 0xFF 0xFF 0xFF 0xFF 0xFF 0xFF
						0xFF 0xFF 0xFF 0xFF 0xFF 0xFF 0xFF 0xFF 0xFF 0xFF 0xFF 0xFF 0xFF 0xFF 0xFF 0xFF
						0xFF 0xFF 0xFF 0xFF 0xFF 0xFF 0xFF 0xFF 0xFF 0xFF 0xFF 0xFF 0xFF 0xFF 0xFF 0xFF
						0xFF 0xFF 0xFF 0xFF 0xFF 0xFF 0xFF 0xFF 0xFF 0xFF 0xFF 0xFF 0xFF 0xFF 0xFF 0xFF
						0xFF 0xFF 0xFF 0xFF 0xFF 0xFF 0xFF 0xFF 0xFF 0xFF 0xFF 0xFF 0xFF 0xFF 0xFF 0xFF
						0xFF 0xFF 0xFF 0xFF 0xFF 0xFF 0xFF 0xFF 0xFF 0xFF 0xFF 0xFF 0xFF 0xFF 0xFF 0xFF
						0xFF 0xFF 0xFF 0xFF 0xFF 0xFF 0xFF 0xFF 0xFF 0xFF 0xFF 0xFF 0xFF 0xFF 0xFF 0xFF
						0xFF 0xFF 0xFF 0xFF 0xFF 0xFF 0xFF 0xFF 0xFF 0xFF 0xFF 0xFF 0xFF 0xFF 0xFF 0xFF
						0xFF 0xFF 0xFF 0xFF 0xFF 0xFF 0xFF 0xFF 0xFF 0xFF 0xFF 0xFF 0xFF 0xFF 0xFF 0xFF
						0xFF 0xFF 0xFF 0xFF 0xFF 0xFF 0xFF 0xFF 0xFF 0xFF 0xFF 0xFF 0xFF 0xFF 0xFF 0xFF
						0xFF 0xFF 0xFF 0xFF 0xFF 0xFF 0xFF 0xFF 0xFF 0xFF 0xFF 0xFF 0xFF 0xFF 0xFF 0xFF
						0xFF 0xFF 0xFF 0xFF 0xFF 0xFF 0xFF 0xFF 0xFF 0xFF 0xFF 0xFF 0xFF 0xFF 0xFF 0xFF
						0xFF 0xFF 0xFF 0xFF 0xFF 0xFF 0xFF 0xFF 0xFF 0xFF 0xFF 0xFF 0xFF 0xFF 0xFF 0xFF
						0xFF 0xFF 0xFF 0xFF 0xFF 0xFF 0xFF 0xFF 0xFF 0xFF 0xFF 0xFF 0xFF 0xFF 0xFF 0xFF
						0xFF 0xFF 0xFF 0xFF 0xFF 0xFF 0xFF 0xFF 0xFF 0xFF 0xFF 0xFF 0xFF 0xFF 0xFF 0xFF
						0xFF 0xFF 0xFF 0xFF 0xFF 0xFF 0xFF 0xFF 0xFF 0xFF 0xFF 0xFF 0xFF 0xFF 0xFF 0xFF
						0xFF 0xFF 0xFF 0xFF 0xFF 0xFF 0xFF 0xFF 0xFF 0xFF 0xFF 0xFF 0xFF 0xFF 0xFF 0xFF
						0xFF 0xFF 0xFF 0xFF 0xFF 0xFF 0xFF 0xFF 0xFF 0xFF 0xFF 0xFF 0xFF 0xFF 0xFF 0xFF
						0xFF 0xFF 0xFF 0xFF 0xFF 0xFF 0xFF 0xFF 0xFF 0xFF 0xFF 0xFF 0xFF 0xFF 0xFF 0xFF
						0xFF 0xFF 0xFF 0xFF 0xFF 0xFF 0xFF 0xFF 0xFF 0xFF 0xFF 0xFF 0xFF 0xFF 0xFF 0xFF
						0xFF 0xFF 0xFF 0xFF 0xFF 0xFF 0xFF 0xFF 0xFF 0xFF 0xFF 0xFF 0xFF 0xFF 0xFF 0xFF
						0xFF 0xFF 0xFF 0xFF 0xFF 0xFF 0xFF 0xFF 0xFF 0xFF 0xFF 0xFF 0xFF 0xFF 0xFF 0xFF
						0xFF 0xFF 0xFF 0xFF 0xFF 0xFF 0xFF 0xFF 0xFF 0xFF 0xFF 0xFF 0xFF 0xFF 0xFF 0xFF
						0xFF 0xFF 0xFF 0xFF 0xFF 0xFF 0xFF 0xFF 0xFF 0xFF 0xFF 0xFF 0xFF 0xFF 0xFF 0xFF
						0xFF 0xFF 0xFF 0xFF 0xFF 0xFF 0xFF 0xFF 0xFF 0xFF 0xFF 0xFF 0xFF 0xFF 0xFF 0xFF
						0xFF 0xFF 0xFF 0xFF 0xFF 0xFF 0xFF 0xFF 0xFF 0xFF 0xFF 0xFF 0xFF 0xFF 0xFF 0xFF
						0xFF 0xFF 0xFF 0xFF 0xFF 0xFF 0xFF 0xFF 0xFF 0xFF 0xFF 0xFF 0xFF 0xFF 0xFF 0xFF
						0xFF 0xFF 0xFF 0xFF 0xFF 0xFF 0xFF 0xFF 0xFF 0xFF 0xFF 0xFF 0xFF 0xFF 0xFF 0xFF
						0xFF 0xFF 0xFF 0xFF 0xFF 0xFF 0xFF 0xFF 0xFF 0xFF 0xFF 0xFF 0xFF 0xFF 0xFF 0xFF
						0xFF 0xFF 0xFF 0xFF 0xFF 0xFF 0xFF 0xFF 0xFF 0xFF 0xFF 0xFF 0xFF 0xFF 0xFF 0xFF
						0xFF 0xFF 0xFF 0xFF 0xFF 0xFF 0xFF 0xFF 0xFF 0xFF 0xFF 0xFF 0xFF 0xFF 0xFF 0xFF
						0xFF 0xFF 0xFF 0xFF 0xFF 0xFF 0xFF 0xFF 0xFF 0xFF 0xFF 0xFF 0xFF 0xFF 0xFF 0xFF
						0xFF 0xFF 0xFF 0xFF 0xFF 0xFF 0xFF 0xFF 0xFF 0xFF 0xFF 0xFF 0xFF 0xFF 0xFF 0xFF
						0xFF 0xFF 0xFF 0xFF 0xFF 0xFF 0xFF 0xFF 0xFF 0xFF 0xFF 0xFF 0xFF 0xFF 0xFF 0xFF
						0xFF 0xFF 0xFF 0xFF 0xFF 0xFF 0xFF 0xFF 0xFF 0xFF 0xFF 0xFF 0xFF 0xFF 0xFF 0xFF
						0xFF 0xFF 0xFF 0xFF 0xFF 0xFF 0xFF 0xFF 0xFF 0xFF 0xFF 0xFF 0xFF 0xFF 0xFF 0xFF
						0xFF 0xFF 0xFF 0xFF 0xFF 0xFF 0xFF 0xFF 0xFF 0xFF 0xFF 0xFF 0xFF 0xFF 0xFF 0xFF
						0xFF 0xFF 0xFF 0xFF 0xFF 0xFF 0xFF 0xFF 0xFF 0xFF 0xFF 0xFF 0xFF 0xFF 0xFF 0xFF
						0xFF 0xFF 0xFF 0xFF 0xFF 0xFF 0xFF 0xFF 0xFF 0xFF 0xFF 0xFF 0xFF 0xFF 0xFF 0xFF
						0xFF 0xFF 0xFF 0xFF 0xFF 0xFF 0xFF 0xFF 0xFF 0xFF 0xFF 0xFF 0xFF 0xFF 0xFF 0xFF
						0xFF 0xFF 0xFF 0xFF 0xFF 0xFF 0xFF 0xFF 0xFF 0xFF 0xFF 0xFF 0xFF 0xFF 0xFF 0xFF
						0xFF 0xFF 0xFF 0xFF 0xFF 0xFF 0xFF 0xFF 0xFF 0xFF 0xFF 0xFF 0xFF 0xFF 0xFF 0xFF
						0xFF 0xFF 0xFF 0xFF 0xFF 0xFF 0xFF 0xFF 0xFF 0xFF 0xFF 0xFF 0xFF 0xFF 0xFF 0xFF
						0xFF 0xFF 0xFF 0xFF 0xFF 0xFF 0xFF 0xFF 0xFF 0xFF 0xFF 0xFF 0xFF 0xFF 0xFF 0x87
						>;
				};
				1080x2400@30 {
					exynos,mode-type = <DRM_MODE_TYPE_DRIVER>;
					exynos,refresh-rate = <30>;
					exynos,hactive = <1080>;
					exynos,hfront-porch = <2>;
					exynos,hsync-len = <2>;
					exynos,hback-porch = <2>;
					exynos,vactive = <2400>;
					exynos,vfront-porch = <8>;
					exynos,vsync-len = <1>;
					exynos,vback-porch = <15>;
					exynos,clock-frequency = <78974>;

					exynos,mode-flags = <MIPI_DSI_CLOCK_NON_CONTINUOUS>;
					exynos,bpc = <8>;
					exynos,lp-mode = <1>;
					exynos,dsc-en = <1>;
					exynos,dsc-count = <1>;
					exynos,dsc-slice-count = <2>;
					exynos,dsc-slice-height = <40>;

					exynos,pps-cmds = <
						0x58
						0x11 0x00 0x00 0x89 0x30 0x80 0x09 0x60
						0x04 0x38 0x00 0x28 0x02 0x1C 0x02 0x1C
						0x02 0x00 0x02 0x0E 0x00 0x20 0x03 0xDD
						0x00 0x07 0x00 0x0C 0x02 0x77 0x02 0x8B
						0x18 0x00 0x10 0xF0 0x03 0x0C 0x20 0x00
						0x06 0x0B 0x0B 0x33 0x0E 0x1C 0x2A 0x38
						0x46 0x54 0x62 0x69 0x70 0x77 0x79 0x7B
						0x7D 0x7E 0x01 0x02 0x01 0x00 0x09 0x40
						0x09 0xBE 0x19 0xFC 0x19 0xFA 0x19 0xF8
						0x1A 0x38 0x1A 0x78 0x1A 0xB6 0x2A 0xF6
						0x2B 0x34 0x2B 0x74 0x3B 0x74 0x6B 0xF4
						0x00
						>;

					exynos,vref-cmds = <
						0x03 0xF0 0x5A 0x5A 0x00
						0x03 0x9F 0xA5 0xA5 0x00
						0x02 0x60 0x00 0x00
						0x03 0x9F 0x5A 0x5A 0x00
						0x02 0xF7 0x0F 0x00
						0x03 0xF0 0xA5 0xA5 0x00
						>;

					exynos,rcd-block-rect = <0 100 1080 2200>;
					exynos,rcd-top-pos = <0 0>;
					exynos,rcd-top-img = /bits/ 8 <
						0xFF 0xFF 0xFF 0xFF 0xFF 0xFF 0xFF 0xFF 0xFF 0xFF 0xFF 0xFF 0xFF 0xFF 0xFF 0xFF
						0xFF 0xFF 0xFF 0xFF 0xFF 0x95 0x00 0x03 0xFF 0xFF 0xFF 0xFF 0xFF 0xFF 0xFF 0xFF
						0xFF 0x38 0x00 0x05 0xFF 0xFF 0xFF 0xFF 0xFF 0xFF 0xFF 0xFF 0xFF 0x36 0x00 0x07
						0xFF 0xFF 0xFF 0xFF 0xFF 0xFF 0xFF 0xFF 0xFF 0x34 0x00 0x09 0xFF 0xFF 0xFF 0xFF
						0xFF 0xFF 0xFF 0xFF 0xFF 0x32 0x00 0x0B 0xFF 0xFF 0xFF 0xFF 0xFF 0xFF 0xFF 0xFF
						0xFF 0x30 0x00 0x0D 0xFF 0xFF 0xFF 0xFF 0xFF 0xFF 0xFF 0xFF 0xFF 0x2E 0x00 0x0F
						0xFF 0xFF 0xFF 0xFF 0xFF 0xFF 0xFF 0xFF 0xFF 0x2C 0x00 0x11 0xFF 0xFF 0xFF 0xFF
						0xFF 0xFF 0xFF 0xFF 0xFF 0x2A 0x00 0x13 0xFF 0xFF 0xFF 0xFF 0xFF 0xFF 0xFF 0xFF
						0xFF 0x28 0x00 0x15 0xFF 0xFF 0xFF 0xFF 0xFF 0xFF 0xFF 0xFF 0xFF 0x26 0x00 0x17
						0xFF 0xFF 0xFF 0xFF 0xFF 0xFF 0xFF 0xFF 0xFF 0x24 0x00 0x19 0xFF 0xFF 0xFF 0xFF
						0xFF 0xFF 0xFF 0xFF 0xFF 0x22 0x00 0x1B 0xFF 0xFF 0xFF 0xFF 0xFF 0xFF 0xFF 0xFF
						0xFF 0x20 0x00 0x1D 0xFF 0xFF 0xFF 0xFF 0xFF 0xFF 0xFF 0xFF 0xFF 0x1E 0x00 0x1F
						0xFF 0xFF 0xFF 0xFF 0xFF 0xFF 0xFF 0xFF 0xFF 0x1C 0x00 0x21 0xFF 0xFF 0xFF 0xFF
						0xFF 0xFF 0xFF 0xFF 0xFF 0x1A 0x00 0x23 0xFF 0xFF 0xFF 0xFF 0xFF 0xFF 0xFF 0xFF
						0xFF 0x18 0x00 0x25 0xFF 0xFF 0xFF 0xFF 0xFF 0xFF 0xFF 0xFF 0xFF 0x16 0x00 0x27
						0xFF 0xFF 0xFF 0xFF 0xFF 0xFF 0xFF 0xFF 0xFF 0x14 0x00 0x29 0xFF 0xFF 0xFF 0xFF
						0xFF 0xFF 0xFF 0xFF 0xFF 0x12 0x00 0x2B 0xFF 0xFF 0xFF 0xFF 0xFF 0xFF 0xFF 0xFF
						0xFF 0x10 0x00 0x2D 0xFF 0xFF 0xFF 0xFF 0xFF 0xFF 0xFF 0xFF 0xFF 0x0E 0x00 0x2F
						0xFF 0xFF 0xFF 0xFF 0xFF 0xFF 0xFF 0xFF 0xFF 0x0C 0x00 0x31 0xFF 0xFF 0xFF 0xFF
						0xFF 0xFF 0xFF 0xFF 0xFF 0x0A 0x00 0x33 0xFF 0xFF 0xFF 0xFF 0xFF 0xFF 0xFF 0xFF
						0xFF 0x08 0x00 0x35 0xFF 0xFF 0xFF 0xFF 0xFF 0xFF 0xFF 0xFF 0xFF 0x06 0x00 0x37
						0xFF 0xFF 0xFF 0xFF 0xFF 0xFF 0xFF 0xFF 0xFF 0x04 0x00 0x39 0xFF 0xFF 0xFF 0xFF
						0xFF 0xFF 0xFF 0xFF 0xFF 0x02 0x00 0x3B 0xFF 0xFF 0xFF 0xFF 0xFF 0xFF 0xFF 0xFF
						0x00 0x3D 0xFF 0xFF 0xFF 0xFF 0xFF 0xFF 0xFF 0xFD 0x00 0x3F 0xFF 0xFF 0xFF 0xFF
						0xFF 0xFF 0xFF 0xFB 0x00 0x41 0xFF 0xFF 0xFF 0xFF 0xFF 0xFF 0xFF 0xF9 0x00 0x43
						0xFF 0xFF 0xFF 0xFF 0xFF 0xFF 0xFF 0xF7 0x00 0x45 0xFF 0xFF 0xFF 0xFF 0xFF 0xFF
						0xFF 0xF5 0x00 0x47 0xFF 0xFF 0xFF 0xFF 0xFF 0xFF 0xFF 0xF3 0x00 0x49 0xFF 0xFF
						0xFF 0xFF 0xFF 0xFF 0xFF 0xF1 0x00 0x4B 0xFF 0xFF 0xFF 0xFF 0xFF 0xFF 0xFF 0xEF
						0x00 0x4D 0xFF 0xFF 0xFF 0xFF 0xFF 0xFF 0xFF 0xED 0x00 0x4F 0xFF 0xFF 0xFF 0xFF
						0xFF 0xFF 0xFF 0xEB 0x00 0x51 0xFF 0xFF 0xFF 0xFF 0xFF 0xFF 0xFF 0xE9 0x00 0x53
						0xFF 0xFF 0xFF 0xFF 0xFF 0xFF 0xFF 0xE7 0x00 0x55 0xFF 0xFF 0xFF 0xFF 0xFF 0xFF
						0xFF 0xE6 0x00 0x55 0xFF 0xFF 0xFF 0xFF 0xFF 0xFF 0xFF 0xE6 0x00 0x55 0xFF 0xFF
						0xFF 0xFF 0xFF 0xFF 0xFF 0xE7 0x00 0x53 0xFF 0xFF 0xFF 0xFF 0xFF 0xFF 0xFF 0xE9
						0x00 0x51 0xFF 0xFF 0xFF 0xFF 0xFF 0xFF 0xFF 0xEB 0x00 0x4F 0xFF 0xFF 0xFF 0xFF
						0xFF 0xFF 0xFF 0xED 0x00 0x4D 0xFF 0xFF 0xFF 0xFF 0xFF 0xFF 0xFF 0xEF 0x00 0x4B
						0xFF 0xFF 0xFF 0xFF 0xFF 0xFF 0xFF 0xF1 0x00 0x49 0xFF 0xFF 0xFF 0xFF 0xFF 0xFF
						0xFF 0xF3 0x00 0x47 0xFF 0xFF 0xFF 0xFF 0xFF 0xFF 0xFF 0xF5 0x00 0x45 0xFF 0xFF
						0xFF 0xFF 0xFF 0xFF 0xFF 0xF7 0x00 0x43 0xFF 0xFF 0xFF 0xFF 0xFF 0xFF 0xFF 0xF9
						0x00 0x41 0xFF 0xFF 0xFF 0xFF 0xFF 0xFF 0xFF 0xFB 0x00 0x3F 0xFF 0xFF 0xFF 0xFF
						0xFF 0xFF 0xFF 0xFD 0x00 0x3D 0xFF 0xFF 0xFF 0xFF 0xFF 0xFF 0xFF 0xFF 0x00 0x3B
						0xFF 0xFF 0xFF 0xFF 0xFF 0xFF 0xFF 0xFF 0xFF 0x02 0x00 0x39 0xFF 0xFF 0xFF 0xFF
						0xFF 0xFF 0xFF 0xFF 0xFF 0x04 0x00 0x37 0xFF 0xFF 0xFF 0xFF 0xFF 0xFF 0xFF 0xFF
						0xFF 0x06 0x00 0x35 0xFF 0xFF 0xFF 0xFF 0xFF 0xFF 0xFF 0xFF 0xFF 0x08 0x00 0x33
						0xFF 0xFF 0xFF 0xFF 0xFF 0xFF 0xFF 0xFF 0xFF 0x0A 0x00 0x31 0xFF 0xFF 0xFF 0xFF
						0xFF 0xFF 0xFF 0xFF 0xFF 0x0C 0x00 0x2F 0xFF 0xFF 0xFF 0xFF 0xFF 0xFF 0xFF 0xFF
						0xFF 0x0E 0x00 0x2D 0xFF 0xFF 0xFF 0xFF 0xFF 0xFF 0xFF 0xFF 0xFF 0x10 0x00 0x2B
						0xFF 0xFF 0xFF 0xFF 0xFF 0xFF 0xFF 0xFF 0xFF 0x12 0x00 0x29 0xFF 0xFF 0xFF 0xFF
						0xFF 0xFF 0xFF 0xFF 0xFF 0x14 0x00 0x27 0xFF 0xFF 0xFF 0xFF 0xFF 0xFF 0xFF 0xFF
						0xFF 0x16 0x00 0x25 0xFF 0xFF 0xFF 0xFF 0xFF 0xFF 0xFF 0xFF 0xFF 0x18 0x00 0x23
						0xFF 0xFF 0xFF 0xFF 0xFF 0xFF 0xFF 0xFF 0xFF 0x1A 0x00 0x21 0xFF 0xFF 0xFF 0xFF
						0xFF 0xFF 0xFF 0xFF 0xFF 0x1C 0x00 0x1F 0xFF 0xFF 0xFF 0xFF 0xFF 0xFF 0xFF 0xFF
						0xFF 0x1E 0x00 0x1D 0xFF 0xFF 0xFF 0xFF 0xFF 0xFF 0xFF 0xFF 0xFF 0x20 0x00 0x1B
						0xFF 0xFF 0xFF 0xFF 0xFF 0xFF 0xFF 0xFF 0xFF 0x22 0x00 0x19 0xFF 0xFF 0xFF 0xFF
						0xFF 0xFF 0xFF 0xFF 0xFF 0x24 0x00 0x17 0xFF 0xFF 0xFF 0xFF 0xFF 0xFF 0xFF 0xFF
						0xFF 0x26 0x00 0x15 0xFF 0xFF 0xFF 0xFF 0xFF 0xFF 0xFF 0xFF 0xFF 0x28 0x00 0x13
						0xFF 0xFF 0xFF 0xFF 0xFF 0xFF 0xFF 0xFF 0xFF 0x2A 0x00 0x11 0xFF 0xFF 0xFF 0xFF
						0xFF 0xFF 0xFF 0xFF 0xFF 0x2C 0x00 0x0F 0xFF 0xFF 0xFF 0xFF 0xFF 0xFF 0xFF 0xFF
						0xFF 0x2E 0x00 0x0D 0xFF 0xFF 0xFF 0xFF 0xFF 0xFF 0xFF 0xFF 0xFF 0x30 0x00 0x0B
						0xFF 0xFF 0xFF 0xFF 0xFF 0xFF 0xFF 0xFF 0xFF 0x32 0x00 0x09 0xFF 0xFF 0xFF 0xFF
						0xFF 0xFF 0xFF 0xFF 0xFF 0x34 0x00 0x07 0xFF 0xFF 0xFF 0xFF 0xFF 0xFF 0xFF 0xFF
						0xFF 0x36 0x00 0x05 0xFF 0xFF 0xFF 0xFF 0xFF 0xFF 0xFF 0xFF 0xFF 0x38 0x00 0x03
						0xFF 0xFF 0xFF 0xFF 0xFF 0xFF 0xFF 0xFF 0xFF 0xFF 0xFF 0xFF 0xFF 0xFF 0xFF 0xFF
						0xFF 0xFF 0xFF 0xFF 0xFF 0xFF 0xFF 0xFF 0xFF 0xFF 0xFF 0xFF 0xFF 0xFF 0xFF 0xFF
						0xFF 0xFF 0xFF 0xFF 0xFF 0xFF 0xFF 0xFF 0xFF 0xFF 0xFF 0xFF 0xFF 0xFF 0xFF 0xFF
						0xFF 0xFF 0xFF 0xFF 0xFF 0xFF 0xFF 0xFF 0xFF 0xFF 0xFF 0xFF 0xFF 0xFF 0xFF 0xFF
						0xFF 0xFF 0xFF 0xFF 0xFF 0xFF 0xFF 0xFF 0xFF 0xFF 0xFF 0xFF 0xFF 0xFF 0xFF 0xFF
						0xFF 0xFF 0xFF 0xFF 0xFF 0xFF 0xFF 0xFF 0xFF 0xFF 0xFF 0xFF 0xFF 0xFF 0xFF 0xFF
						0xFF 0xFF 0xFF 0xFF 0xFF 0xFF 0xFF 0xFF 0xFF 0xFF 0xFF 0xFF 0xFF 0xFF 0xFF 0xFF
						0xFF 0xFF 0xFF 0x2B
						>;

					exynos,rcd-bot-pos = <0 2300>;
					exynos,rcd-bot-img = /bits/ 8 <
						0xFF 0xFF 0xFF 0xFF 0xFF 0xFF 0xFF 0xFF 0xFF 0xFF 0xFF 0xFF 0xFF 0xFF 0xFF 0xFF
						0xFF 0xFF 0xFF 0xFF 0xFF 0xFF 0xFF 0xFF 0xFF 0xFF 0xFF 0xFF 0xFF 0xFF 0xFF 0xFF
						0xFF 0xFF 0xFF 0xFF 0xFF 0xFF 0xFF 0xFF 0xFF 0xFF 0xFF 0xFF 0xFF 0xFF 0xFF 0xFF
						0xFF 0xFF 0xFF 0xFF 0xFF 0xFF 0xFF 0xFF 0xFF 0xFF 0xFF 0xFF 0xFF 0xFF 0xFF 0xFF
						0xFF 0xFF 0xFF 0xFF 0xFF 0xFF 0xFF 0xFF 0xFF 0xFF 0xFF 0xFF 0xFF 0xFF 0xFF 0xFF
						0xFF 0xFF 0xFF 0xFF 0xFF 0xFF 0xFF 0xFF 0xFF 0xFF 0xFF 0xFF 0xFF 0xFF 0xFF 0xFF
						0xFF 0xFF 0xFF 0xFF 0xFF 0xFF 0xFF 0xFF 0xFF 0xFF 0xFF 0xFF 0xFF 0xFF 0xFF 0xFF
						0xFF 0xFF 0xFF 0xFF 0xFF 0xFF 0xFF 0xFF 0xFF 0xFF 0xFF 0xFF 0xFF 0xFF 0xFF 0xFF
						0xFF 0xFF 0xFF 0xFF 0xFF 0xFF 0xFF 0xFF 0xFF 0xFF 0xFF 0xFF 0xFF 0xFF 0xFF 0xFF
						0xFF 0xFF 0xFF 0xFF 0xFF 0xFF 0xFF 0xFF 0xFF 0xFF 0xFF 0xFF 0xFF 0xFF 0xFF 0xFF
						0xFF 0xFF 0xFF 0xFF 0xFF 0xFF 0xFF 0xFF 0xFF 0xFF 0xFF 0xFF 0xFF 0xFF 0xFF 0xFF
						0xFF 0xFF 0xFF 0xFF 0xFF 0xFF 0xFF 0xFF 0xFF 0xFF 0xFF 0xFF 0xFF 0xFF 0xFF 0xFF
						0xFF 0xFF 0xFF 0xFF 0xFF 0xFF 0xFF 0xFF 0xFF 0xFF 0xFF 0xFF 0xFF 0xFF 0xFF 0xFF
						0xFF 0xFF 0xFF 0xFF 0xFF 0xFF 0xFF 0xFF 0xFF 0xFF 0xFF 0xFF 0xFF 0xFF 0xFF 0xFF
						0xFF 0xFF 0xFF 0xFF 0xFF 0xFF 0xFF 0xFF 0xFF 0xFF 0xFF 0xFF 0xFF 0xFF 0xFF 0xFF
						0xFF 0xFF 0xFF 0xFF 0xFF 0xFF 0xFF 0xFF 0xFF 0xFF 0xFF 0xFF 0xFF 0xFF 0xFF 0xFF
						0xFF 0xFF 0xFF 0xFF 0xFF 0xFF 0xFF 0xFF 0xFF 0xFF 0xFF 0xFF 0xFF 0xFF 0xFF 0xFF
						0xFF 0xFF 0xFF 0xFF 0xFF 0xFF 0xFF 0xFF 0xFF 0xFF 0xFF 0xFF 0xFF 0xFF 0xFF 0xFF
						0xFF 0xFF 0xFF 0xFF 0xFF 0xFF 0xFF 0xFF 0xFF 0xFF 0xFF 0xFF 0xFF 0xFF 0xFF 0xFF
						0xFF 0xFF 0xFF 0xFF 0xFF 0xFF 0xFF 0xFF 0xFF 0xFF 0xFF 0xFF 0xFF 0xFF 0xFF 0xFF
						0xFF 0xFF 0xFF 0xFF 0xFF 0xFF 0xFF 0xFF 0xFF 0xFF 0xFF 0xFF 0xFF 0xFF 0xFF 0xFF
						0xFF 0xFF 0xFF 0xFF 0xFF 0xFF 0xFF 0xFF 0xFF 0xFF 0xFF 0xFF 0xFF 0xFF 0xFF 0xFF
						0xFF 0xFF 0xFF 0xFF 0xFF 0xFF 0xFF 0xFF 0xFF 0xFF 0xFF 0xFF 0xFF 0xFF 0xFF 0xFF
						0xFF 0xFF 0xFF 0xFF 0xFF 0xFF 0xFF 0xFF 0xFF 0xFF 0xFF 0xFF 0xFF 0xFF 0xFF 0xFF
						0xFF 0xFF 0xFF 0xFF 0xFF 0xFF 0xFF 0xFF 0xFF 0xFF 0xFF 0xFF 0xFF 0xFF 0xFF 0xFF
						0xFF 0xFF 0xFF 0xFF 0xFF 0xFF 0xFF 0xFF 0xFF 0xFF 0xFF 0xFF 0xFF 0xFF 0xFF 0xFF
						0xFF 0xFF 0xFF 0xFF 0xFF 0xFF 0xFF 0xFF 0xFF 0xFF 0xFF 0xFF 0xFF 0xFF 0xFF 0xFF
						0xFF 0xFF 0xFF 0xFF 0xFF 0xFF 0xFF 0xFF 0xFF 0xFF 0xFF 0xFF 0xFF 0xFF 0xFF 0xFF
						0xFF 0xFF 0xFF 0xFF 0xFF 0xFF 0xFF 0xFF 0xFF 0xFF 0xFF 0xFF 0xFF 0xFF 0xFF 0xFF
						0xFF 0xFF 0xFF 0xFF 0xFF 0xFF 0xFF 0xFF 0xFF 0xFF 0xFF 0xFF 0xFF 0xFF 0xFF 0xFF
						0xFF 0xFF 0xFF 0xFF 0xFF 0xFF 0xFF 0xFF 0xFF 0xFF 0xFF 0xFF 0xFF 0xFF 0xFF 0xFF
						0xFF 0xFF 0xFF 0xFF 0xFF 0xFF 0xFF 0xFF 0xFF 0xFF 0xFF 0xFF 0xFF 0xFF 0xFF 0xFF
						0xFF 0xFF 0xFF 0xFF 0xFF 0xFF 0xFF 0xFF 0xFF 0xFF 0xFF 0xFF 0xFF 0xFF 0xFF 0xFF
						0xFF 0xFF 0xFF 0xFF 0xFF 0xFF 0xFF 0xFF 0xFF 0xFF 0xFF 0xFF 0xFF 0xFF 0xFF 0xFF
						0xFF 0xFF 0xFF 0xFF 0xFF 0xFF 0xFF 0xFF 0xFF 0xFF 0xFF 0xFF 0xFF 0xFF 0xFF 0xFF
						0xFF 0xFF 0xFF 0xFF 0xFF 0xFF 0xFF 0xFF 0xFF 0xFF 0xFF 0xFF 0xFF 0xFF 0xFF 0xFF
						0xFF 0xFF 0xFF 0xFF 0xFF 0xFF 0xFF 0xFF 0xFF 0xFF 0xFF 0xFF 0xFF 0xFF 0xFF 0xFF
						0xFF 0xFF 0xFF 0xFF 0xFF 0xFF 0xFF 0xFF 0xFF 0xFF 0xFF 0xFF 0xFF 0xFF 0xFF 0xFF
						0xFF 0xFF 0xFF 0xFF 0xFF 0xFF 0xFF 0xFF 0xFF 0xFF 0xFF 0xFF 0xFF 0xFF 0xFF 0xFF
						0xFF 0xFF 0xFF 0xFF 0xFF 0xFF 0xFF 0xFF 0xFF 0xFF 0xFF 0xFF 0xFF 0xFF 0xFF 0xFF
						0xFF 0xFF 0xFF 0xFF 0xFF 0xFF 0xFF 0xFF 0xFF 0xFF 0xFF 0xFF 0xFF 0xFF 0xFF 0xFF
						0xFF 0xFF 0xFF 0xFF 0xFF 0xFF 0xFF 0xFF 0xFF 0xFF 0xFF 0xFF 0xFF 0xFF 0xFF 0xFF
						0xFF 0xFF 0xFF 0xFF 0xFF 0xFF 0xFF 0xFF 0xFF 0xFF 0xFF 0xFF 0xFF 0xFF 0xFF 0xFF
						0xFF 0xFF 0xFF 0xFF 0xFF 0xFF 0xFF 0xFF 0xFF 0xFF 0xFF 0xFF 0xFF 0xFF 0xFF 0xFF
						0xFF 0xFF 0xFF 0xFF 0xFF 0xFF 0xFF 0xFF 0xFF 0xFF 0xFF 0xFF 0xFF 0xFF 0xFF 0xFF
						0xFF 0xFF 0xFF 0xFF 0xFF 0xFF 0xFF 0xFF 0xFF 0xFF 0xFF 0xFF 0xFF 0xFF 0xFF 0xFF
						0xFF 0xFF 0xFF 0xFF 0xFF 0xFF 0xFF 0xFF 0xFF 0xFF 0xFF 0xFF 0xFF 0xFF 0xFF 0xFF
						0xFF 0xFF 0xFF 0xFF 0xFF 0xFF 0xFF 0xFF 0xFF 0xFF 0xFF 0xFF 0xFF 0xFF 0xFF 0xFF
						0xFF 0xFF 0xFF 0xFF 0xFF 0xFF 0xFF 0xFF 0xFF 0xFF 0xFF 0xFF 0xFF 0xFF 0xFF 0xFF
						0xFF 0xFF 0xFF 0xFF 0xFF 0xFF 0xFF 0xFF 0xFF 0xFF 0xFF 0xFF 0xFF 0xFF 0xFF 0xFF
						0xFF 0xFF 0xFF 0xFF 0xFF 0xFF 0xFF 0xFF 0xFF 0xFF 0xFF 0xFF 0xFF 0xFF 0xFF 0xFF
						0xFF 0xFF 0xFF 0xFF 0xFF 0xFF 0xFF 0xFF 0xFF 0xFF 0xFF 0xFF 0xFF 0xFF 0xFF 0xFF
						0xFF 0xFF 0xFF 0xFF 0xFF 0xFF 0xFF 0xFF 0xFF 0xFF 0xFF 0xFF 0xFF 0xFF 0xFF 0x87
						>;

				};
			};
		};
	};
};
